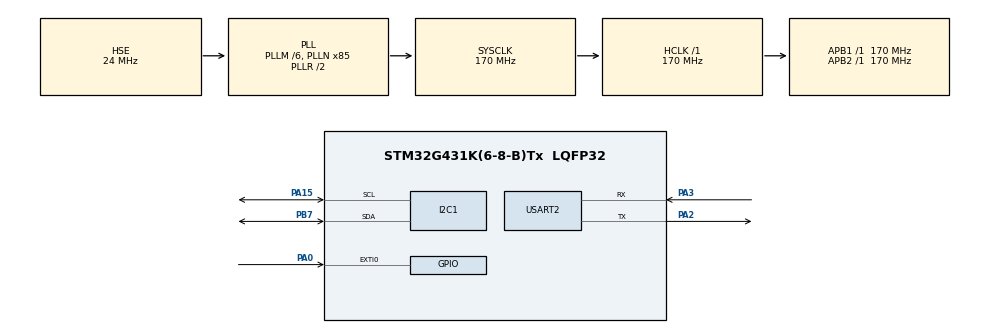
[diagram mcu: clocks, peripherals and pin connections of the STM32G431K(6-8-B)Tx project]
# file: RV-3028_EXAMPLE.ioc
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I2C1.Timing=0x40B285C2
Mcu.Family=STM32G4
Mcu.Name=STM32G431K(6-8-B)Tx
Mcu.Package=LQFP32
NVIC.EXTI0_IRQn=true\:0\:0\:false\:false\:true\:true\:true\:true
NVIC.I2C1_ER_IRQn=true\:0\:0\:false\:false\:true\:true\:true\:true
NVIC.I2C1_EV_IRQn=true\:0\:0\:false\:false\:true\:true\:true\:true
NVIC.PriorityGroup=NVIC_PRIORITYGROUP_4
PA0.GPIO_ModeDefaultEXTI=GPIO_MODE_IT_FALLING
PA0.GPIO_PuPd=GPIO_PULLUP
PA0.Signal=GPXTI0
PA13.Mode=Serial_Wire
PA13.Signal=SYS_JTMS-SWDIO
PA14.Mode=Serial_Wire
PA14.Signal=SYS_JTCK-SWCLK
PA15.Mode=I2C
PA15.Signal=I2C1_SCL
PA2.Mode=Asynchronous
PA2.Signal=USART2_TX
PA3.Mode=Asynchronous
PA3.Signal=USART2_RX
PB7.Mode=I2C
PB7.Signal=I2C1_SDA
PF0-OSC_IN.Mode=HSE-External-Oscillator
PF0-OSC_IN.Signal=RCC_OSC_IN
PF1-OSC_OUT.Mode=HSE-External-Oscillator
PF1-OSC_OUT.Signal=RCC_OSC_OUT
ProjectManager.HeapSize=0x200
ProjectManager.StackSize=0x400
ProjectManager.TargetToolchain=STM32CubeIDE
RCC.ADC12Freq_Value=170000000
RCC.AHBFreq_Value=170000000
RCC.APB1Freq_Value=170000000
RCC.APB1TimFreq_Value=170000000
RCC.APB2Freq_Value=170000000
RCC.APB2TimFreq_Value=170000000
RCC.CortexFreq_Value=170000000
RCC.EXTERNAL_CLOCK_VALUE=12288000
RCC.HCLKFreq_Value=170000000
RCC.HSE_VALUE=24000000
RCC.HSI48_VALUE=48000000
RCC.HSI_VALUE=16000000
RCC.LSE_VALUE=32768
RCC.PLLM=RCC_PLLM_DIV6
RCC.PLLN=85
RCC.PLLSourceVirtual=RCC_PLLSOURCE_HSE
RCC.SYSCLKFreq_VALUE=170000000
RCC.SYSCLKSource=RCC_SYSCLKSOURCE_PLLCLK
RCC.USBFreq_Value=170000000
RCC.VCOOutputFreq_Value=340000000
USART2.VirtualMode-Asynchronous=VM_ASYNC
VP_SYS_VS_DBSignals.Mode=DisableDeadBatterySignals
board=custom

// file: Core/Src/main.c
/* USER CODE BEGIN Header */
/**
  ******************************************************************************
  * @file           : main.c
  * @brief          : Main program body
  ******************************************************************************
  * @attention
  *
  * Copyright (c) 2026 STMicroelectronics.
  * All rights reserved.
  *
  * This software is licensed under terms that can be found in the LICENSE file
  * in the root directory of this software component.
  * If no LICENSE file comes with this software, it is provided AS-IS.
  *
  ******************************************************************************
  */
/* USER CODE END Header */
#include "main.h"

/* USER CODE BEGIN Includes */

#include "rv3028.h"
#include "rv3028_i2c.h"
#include "nano_rtc.h"

/* USER CODE END Includes */

I2C_HandleTypeDef hi2c1;

UART_HandleTypeDef huart2;

void SystemClock_Config(void);
static void MX_GPIO_Init(void);
static void MX_I2C1_Init(void);
static void MX_USART2_UART_Init(void);

int main(void)
{

  /* MCU Configuration--------------------------------------------------------*/

  /* Reset of all peripherals, Initializes the Flash interface and the Systick. */
  HAL_Init();

  /* Configure the system clock */
  SystemClock_Config();

  /* Initialize all configured peripherals */
  MX_GPIO_Init();
  MX_I2C1_Init();
  MX_USART2_UART_Init();
  /* USER CODE BEGIN 2 */

  HAL_Delay(500);

/* Start the NANO-RTC Serial Clock. */
  NANO_RTC_Run();

  /* USER CODE END 2 */

  /* Infinite loop */
  while (1)
  {

  }
}

void SystemClock_Config(void)
{
  RCC_OscInitTypeDef RCC_OscInitStruct = {0};
  RCC_ClkInitTypeDef RCC_ClkInitStruct = {0};

  /** Configure the main internal regulator output voltage
  */
  HAL_PWREx_ControlVoltageScaling(PWR_REGULATOR_VOLTAGE_SCALE1_BOOST);

  /** Initializes the RCC Oscillators according to the specified parameters
  * in the RCC_OscInitTypeDef structure.
  */
  RCC_OscInitStruct.OscillatorType = RCC_OSCILLATORTYPE_HSE;
  RCC_OscInitStruct.HSEState = RCC_HSE_ON;
  RCC_OscInitStruct.PLL.PLLState = RCC_PLL_ON;
  RCC_OscInitStruct.PLL.PLLSource = RCC_PLLSOURCE_HSE;
  RCC_OscInitStruct.PLL.PLLM = RCC_PLLM_DIV6;
  RCC_OscInitStruct.PLL.PLLN = 85;
  RCC_OscInitStruct.PLL.PLLP = RCC_PLLP_DIV2;
  RCC_OscInitStruct.PLL.PLLQ = RCC_PLLQ_DIV2;
  RCC_OscInitStruct.PLL.PLLR = RCC_PLLR_DIV2;
  if (HAL_RCC_OscConfig(&RCC_OscInitStruct) != HAL_OK)
  {
    Error_Handler();
  }

  /** Initializes the CPU, AHB and APB buses clocks
  */
  RCC_ClkInitStruct.ClockType = RCC_CLOCKTYPE_HCLK|RCC_CLOCKTYPE_SYSCLK
                              |RCC_CLOCKTYPE_PCLK1|RCC_CLOCKTYPE_PCLK2;
  RCC_ClkInitStruct.SYSCLKSource = RCC_SYSCLKSOURCE_PLLCLK;
  RCC_ClkInitStruct.AHBCLKDivider = RCC_SYSCLK_DIV1;
  RCC_ClkInitStruct.APB1CLKDivider = RCC_HCLK_DIV1;
  RCC_ClkInitStruct.APB2CLKDivider = RCC_HCLK_DIV1;

  if (HAL_RCC_ClockConfig(&RCC_ClkInitStruct, FLASH_LATENCY_4) != HAL_OK)
  {
    Error_Handler();
  }
}

static void MX_I2C1_Init(void)
{

  hi2c1.Instance = I2C1;
  hi2c1.Init.Timing = 0x40B285C2;
  hi2c1.Init.OwnAddress1 = 0;
  hi2c1.Init.AddressingMode = I2C_ADDRESSINGMODE_7BIT;
  hi2c1.Init.DualAddressMode = I2C_DUALADDRESS_DISABLE;
  hi2c1.Init.OwnAddress2 = 0;
  hi2c1.Init.OwnAddress2Masks = I2C_OA2_NOMASK;
  hi2c1.Init.GeneralCallMode = I2C_GENERALCALL_DISABLE;
  hi2c1.Init.NoStretchMode = I2C_NOSTRETCH_DISABLE;
  if (HAL_I2C_Init(&hi2c1) != HAL_OK)
  {
    Error_Handler();
  }

  /** Configure Analogue filter
  */
  if (HAL_I2CEx_ConfigAnalogFilter(&hi2c1, I2C_ANALOGFILTER_ENABLE) != HAL_OK)
  {
    Error_Handler();
  }

  /** Configure Digital filter
  */
  if (HAL_I2CEx_ConfigDigitalFilter(&hi2c1, 0) != HAL_OK)
  {
    Error_Handler();
  }

}

static void MX_USART2_UART_Init(void)
{

  huart2.Instance = USART2;
  huart2.Init.BaudRate = 115200;
  huart2.Init.WordLength = UART_WORDLENGTH_8B;
  huart2.Init.StopBits = UART_STOPBITS_1;
  huart2.Init.Parity = UART_PARITY_NONE;
  huart2.Init.Mode = UART_MODE_TX_RX;
  huart2.Init.HwFlowCtl = UART_HWCONTROL_NONE;
  huart2.Init.OverSampling = UART_OVERSAMPLING_16;
  huart2.Init.OneBitSampling = UART_ONE_BIT_SAMPLE_DISABLE;
  huart2.Init.ClockPrescaler = UART_PRESCALER_DIV1;
  huart2.AdvancedInit.AdvFeatureInit = UART_ADVFEATURE_NO_INIT;
  if (HAL_UART_Init(&huart2) != HAL_OK)
  {
    Error_Handler();
  }
  if (HAL_UARTEx_SetTxFifoThreshold(&huart2, UART_TXFIFO_THRESHOLD_1_8) != HAL_OK)
  {
    Error_Handler();
  }
  if (HAL_UARTEx_SetRxFifoThreshold(&huart2, UART_RXFIFO_THRESHOLD_1_8) != HAL_OK)
  {
    Error_Handler();
  }
  if (HAL_UARTEx_DisableFifoMode(&huart2) != HAL_OK)
  {
    Error_Handler();
  }

}

static void MX_GPIO_Init(void)
{
  GPIO_InitTypeDef GPIO_InitStruct = {0};

  /* GPIO Ports Clock Enable */
  __HAL_RCC_GPIOF_CLK_ENABLE();
  __HAL_RCC_GPIOA_CLK_ENABLE();
  __HAL_RCC_GPIOB_CLK_ENABLE();

  /*Configure GPIO pin : PA0 */
  GPIO_InitStruct.Pin = GPIO_PIN_0;
  GPIO_InitStruct.Mode = GPIO_MODE_IT_FALLING;
  GPIO_InitStruct.Pull = GPIO_PULLUP;
  HAL_GPIO_Init(GPIOA, &GPIO_InitStruct);

  /* EXTI interrupt init*/
  HAL_NVIC_SetPriority(EXTI0_IRQn, 0, 0);
  HAL_NVIC_EnableIRQ(EXTI0_IRQn);

}

void Error_Handler(void)
{
  __disable_irq();
  while (1)
  {
  }
}
